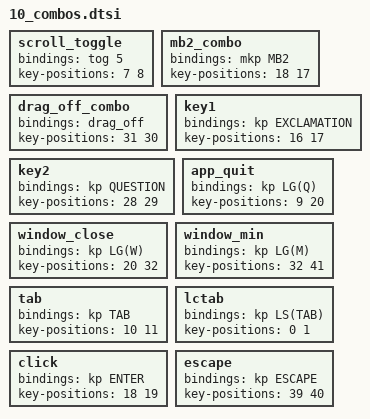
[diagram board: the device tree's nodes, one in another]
/* ============================================================
 * 10_combos.dtsi — コンボ定義
 *
 * combos { compatible = "zmk,combos"; } の内側でインクルードされる。
 * ============================================================ */

scroll_toggle {
    bindings = <&tog 5>;
    key-positions = <7 8>;
};

mb2_combo {
    bindings = <&mkp MB2>;
    key-positions = <18 17>;
};

drag_off_combo {
    bindings = <&drag_off>;
    key-positions = <31 30>;
};

key1 {
    bindings = <&kp EXCLAMATION>;
    key-positions = <16 17>;
};

key2 {
    bindings = <&kp QUESTION>;
    key-positions = <28 29>;
};

app_quit {
    bindings = <&kp LG(Q)>;
    key-positions = <9 20>;
};

window_close {
    bindings = <&kp LG(W)>;
    key-positions = <20 32>;
};

window_min {
    bindings = <&kp LG(M)>;
    key-positions = <32 41>;
};

tab {
    bindings = <&kp TAB>;
    key-positions = <10 11>;
};

lctab {
    bindings = <&kp LS(TAB)>;
    key-positions = <0 1>;
};

click {
    bindings = <&kp ENTER>;
    key-positions = <18 19>;
};

escape {
    bindings = <&kp ESCAPE>;
    key-positions = <39 40>;
};
